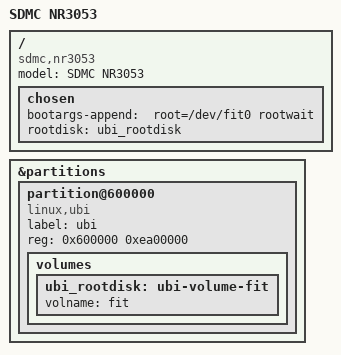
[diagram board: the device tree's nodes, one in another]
// SPDX-License-Identifier: GPL-2.0-or-later OR MIT

/dts-v1/;
#include "mt7981b-sdmc-nr3053.dtsi"

/ {
	model = "SDMC NR3053";
	compatible = "sdmc,nr3053", "mediatek,mt7981";

	chosen {
		bootargs-append = " root=/dev/fit0 rootwait";
		rootdisk = <&ubi_rootdisk>;
	};
};

&partitions {
	partition@600000 {
		label = "ubi";
		reg = <0x600000 0xea00000>;
				compatible = "linux,ubi";

				volumes {
					ubi_rootdisk: ubi-volume-fit {
						volname = "fit";
					};
				};
	};
};
